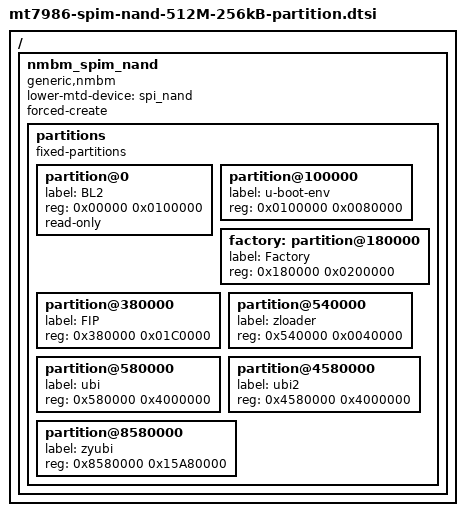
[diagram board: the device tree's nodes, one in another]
/*
 * Zyxel partition layout on below condition:
 *   flash flash size is 512 MB 
 *   flash block size is 256 KB
 * Because NMBM mechanism, partition layout will diference
 * with total block numbers and block size.
 */
/ {
	nmbm_spim_nand {
		compatible = "generic,nmbm";

		#address-cells = <1>;
		#size-cells = <1>;

		lower-mtd-device = <&spi_nand>;
		forced-create;

		partitions {
			compatible = "fixed-partitions";
			#address-cells = <1>;
			#size-cells = <1>;

			partition@0 {
				label = "BL2";
				reg = <0x00000 0x0100000>;
				read-only;
			};

			partition@100000 {
				label = "u-boot-env";
				reg = <0x0100000 0x0080000>;
			};

			factory: partition@180000 {
				label = "Factory";
				reg = <0x180000 0x0200000>;
			};

			partition@380000 {
				label = "FIP";
				reg = <0x380000 0x01C0000>;
			};

			partition@540000 {
				label = "zloader";
				reg = <0x540000 0x0040000>;
			};

			partition@580000 {
				label = "ubi";
				reg = <0x580000 0x4000000>;
			};

			partition@4580000 {
				label = "ubi2";
				reg = <0x4580000 0x4000000>;
			};

			partition@8580000 {
				label = "zyubi";
				reg = <0x8580000 0x15A80000>;
			};
		};
	};
};
